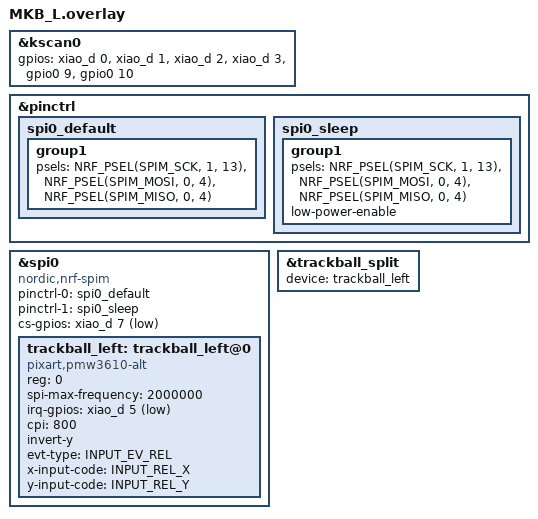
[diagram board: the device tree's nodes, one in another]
#include <zephyr/dt-bindings/input/input-event-codes.h>
#include "MKB.dtsi"


&kscan0 {
  gpios = <&xiao_d  0 (GPIO_ACTIVE_HIGH)>
        , <&xiao_d  1 (GPIO_ACTIVE_HIGH)>
        , <&xiao_d  2 (GPIO_ACTIVE_HIGH)>
        , <&xiao_d  3 (GPIO_ACTIVE_HIGH)>
        , <&gpio0   9 (GPIO_ACTIVE_HIGH)>
        , <&gpio0  10 (GPIO_ACTIVE_HIGH)>
        ;
};


&pinctrl {
    spi0_default: spi0_default {
        group1 {
            psels = <NRF_PSEL(SPIM_SCK,  1, 13)>,
                    <NRF_PSEL(SPIM_MOSI, 0, 4)>,
                    <NRF_PSEL(SPIM_MISO, 0, 4)>;
        };
    };

    spi0_sleep: spi0_sleep {
        group1 {
            psels = <NRF_PSEL(SPIM_SCK,  1, 13)>,
                    <NRF_PSEL(SPIM_MOSI, 0, 4)>,
                    <NRF_PSEL(SPIM_MISO, 0, 4)>;
            low-power-enable;
        };
    };
};

&spi0 {
    status = "okay";
    compatible = "nordic,nrf-spim";
    pinctrl-0 = <&spi0_default>;
    pinctrl-1 = <&spi0_sleep>;
    pinctrl-names = "default", "sleep";
    cs-gpios = <&xiao_d 7 GPIO_ACTIVE_LOW>;

    trackball_left: trackball_left@0 {
        status = "okay";
        compatible = "pixart,pmw3610-alt";
        reg = <0>;
        spi-max-frequency = <2000000>;
        irq-gpios = <&xiao_d 5 (GPIO_ACTIVE_LOW | GPIO_PULL_UP)>;
        cpi = <800>;
        // swap-xy; /* optional */
        // invert-x; /* optional */
        invert-y; /* optional */
        evt-type = <INPUT_EV_REL>;
        x-input-code = <INPUT_REL_X>;
        y-input-code = <INPUT_REL_Y>;
    };
};


&trackball_split {
    device = <&trackball_left>;
};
